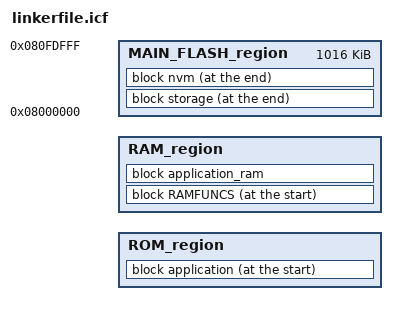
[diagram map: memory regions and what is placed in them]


/*###ICF### Section handled by ICF editor, don't touch! ****/
/*-Editor annotation file-*/
/* IcfEditorFile="$TOOLKIT_DIR$\config\ide\IcfEditor\cortex_v1_0.xml" */
/* Version 4.1.1 */

/*-Memory Regions*/
  define symbol __ICFEDIT_region_ROM_start__ = 0x8000000;
  define symbol __ICFEDIT_region_ROM_end__   = (0x8000000+0xfe000-1);
  define symbol __ICFEDIT_region_RAM_start__ = 0x20000000;
  define symbol __ICFEDIT_region_RAM_end__   = (0x20000000+0x20000-1);

/**** End of ICF editor section. ###ICF###*/
define memory mem with size = 4G;
define region ROM_region   = mem:[from __ICFEDIT_region_ROM_start__   to __ICFEDIT_region_ROM_end__];
define region RAM_region   = mem:[from __ICFEDIT_region_RAM_start__   to __ICFEDIT_region_RAM_end__];
define region MAIN_FLASH_region   = mem:[from 0x8000000   to (0x8000000+0xfe000-1)];

define block CSTACK with alignment = 8
{
  section .stack
};

define block RAMFUNCS with alignment = 8
{
};

/* Note that "expanding size" is not used yet due to failures in 8.30.1 */
define block HEAP with alignment = 8
{
  section .heap
};


define block nvm with alignment = 8192
{
  section SIMEE,
};
keep { block nvm };

define block storage with alignment = 8192
{
  section INTERNAL_STORAGE,
};
keep { block storage };
define block application with fixed order
{
  readonly section .intvec,
  readonly
};

define block application_ram with fixed order
{
  block CSTACK,
  readwrite,
  block HEAP
};

initialize by copy { readwrite };

do not initialize
{
 section .noinit,
 section .stack,
 section .heap
};

keep { section .intvec };
"application":
place at start of ROM_region { block application };

"storage_regions":
place at end of MAIN_FLASH_region {
  block storage,

  block nvm,
};

"ramfuncs":
place at start of RAM_region { 
  block RAMFUNCS,
};

"application_ram":
place in RAM_region {
  block application_ram,
};
